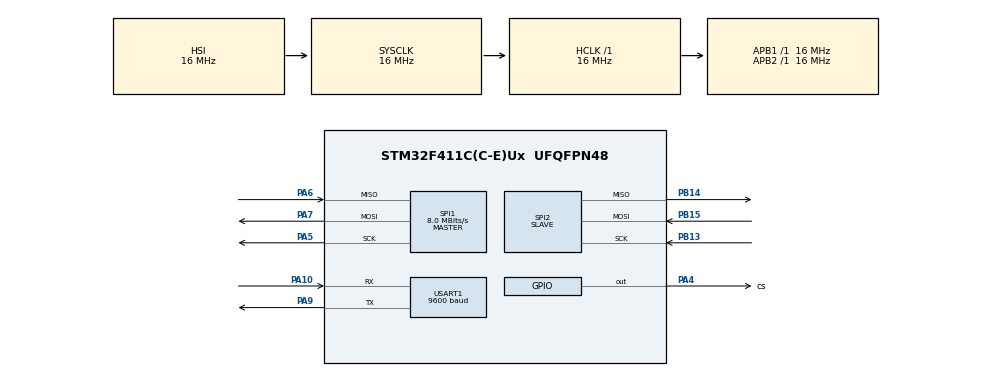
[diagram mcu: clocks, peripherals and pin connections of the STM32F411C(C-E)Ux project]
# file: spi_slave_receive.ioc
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Mcu.Family=STM32F4
Mcu.Name=STM32F411C(C-E)Ux
Mcu.Package=UFQFPN48
NVIC.PriorityGroup=NVIC_PRIORITYGROUP_4
NVIC.SPI2_IRQn=true\:0\:0\:false\:false\:true\:true\:true\:true
PA10.Mode=Asynchronous
PA10.Signal=USART1_RX
PA13.Mode=Serial_Wire
PA13.Signal=SYS_JTMS-SWDIO
PA14.Mode=Serial_Wire
PA14.Signal=SYS_JTCK-SWCLK
PA4.GPIO_Label=cs
PA4.Signal=GPIO_Output
PA5.Mode=Full_Duplex_Master
PA5.Signal=SPI1_SCK
PA6.Mode=Full_Duplex_Master
PA6.Signal=SPI1_MISO
PA7.Mode=Full_Duplex_Master
PA7.Signal=SPI1_MOSI
PA9.Mode=Asynchronous
PA9.Signal=USART1_TX
PB12.Signal=SPI2_NSS
PB13.Mode=Full_Duplex_Slave
PB13.Signal=SPI2_SCK
PB14.Mode=Full_Duplex_Slave
PB14.Signal=SPI2_MISO
PB15.Mode=Full_Duplex_Slave
PB15.Signal=SPI2_MOSI
PH0\ -\ OSC_IN.Mode=HSE-External-Oscillator
PH0\ -\ OSC_IN.Signal=RCC_OSC_IN
PH1\ -\ OSC_OUT.Mode=HSE-External-Oscillator
PH1\ -\ OSC_OUT.Signal=RCC_OSC_OUT
ProjectManager.HeapSize=0x200
ProjectManager.StackSize=0x400
ProjectManager.TargetToolchain=STM32CubeIDE
RCC.AHBFreq_Value=16000000
RCC.APB1Freq_Value=16000000
RCC.APB2Freq_Value=16000000
RCC.CortexFreq_Value=16000000
RCC.HSE_VALUE=25000000
RCC.HSI_VALUE=16000000
RCC.LSE_VALUE=32768
RCC.SYSCLKFreq_VALUE=16000000
RCC.VCOOutputFreq_Value=192000000
SPI1.CalculateBaudRate=8.0 MBits/s
SPI1.Direction=SPI_DIRECTION_2LINES
SPI1.Mode=SPI_MODE_MASTER
SPI1.VirtualType=VM_MASTER
SPI2.Direction=SPI_DIRECTION_2LINES
SPI2.Mode=SPI_MODE_SLAVE
SPI2.VirtualType=VM_SLAVE
USART1.BaudRate=9600
USART1.VirtualMode=VM_ASYNC
board=custom

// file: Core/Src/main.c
/* USER CODE BEGIN Header */
/* USER CODE END Header */
#include "main.h"

/* USER CODE BEGIN Includes */
#include "string.h"
/* USER CODE END Includes */

SPI_HandleTypeDef hspi1;
SPI_HandleTypeDef hspi2;

UART_HandleTypeDef huart1;

/* USER CODE BEGIN PV */
uint8_t tx_master[] = "len\r\n";
uint8_t rx_slave[1] = {0};
uint8_t rx_buffer[10];
uint8_t idx = 0;
/* USER CODE END PV */

void SystemClock_Config(void);
static void MX_GPIO_Init(void);
static void MX_SPI2_Init(void);
static void MX_USART1_UART_Init(void);
static void MX_SPI1_Init(void);

/* USER CODE BEGIN 0 */
void HAL_SPI_RxCpltCallback(SPI_HandleTypeDef *hspi)
{
	UNUSED(hspi);
	if(hspi->Instance == SPI2)
	{
		HAL_SPI_Receive_IT(&hspi2, rx_slave, 1);
		rx_buffer[idx++] = rx_slave[0];
		if(rx_slave[0] == '\n')
			idx = 0;

	}
}
/* USER CODE END 0 */

int main(void)
{

  /* MCU Configuration--------------------------------------------------------*/

  /* Reset of all peripherals, Initializes the Flash interface and the Systick. */
  HAL_Init();

  /* Configure the system clock */
  SystemClock_Config();

  /* Initialize all configured peripherals */
  MX_GPIO_Init();
  MX_SPI2_Init();
  MX_USART1_UART_Init();
  MX_SPI1_Init();
  /* USER CODE BEGIN 2 */
  HAL_SPI_Receive_IT(&hspi2, rx_slave, 1);
  HAL_SPI_Transmit(&hspi1, tx_master, 3, 1000);
  /* USER CODE END 2 */

  /* Infinite loop */

}

void SystemClock_Config(void)
{
  RCC_OscInitTypeDef RCC_OscInitStruct = {0};
  RCC_ClkInitTypeDef RCC_ClkInitStruct = {0};

  /** Configure the main internal regulator output voltage
  */
  __HAL_RCC_PWR_CLK_ENABLE();
  __HAL_PWR_VOLTAGESCALING_CONFIG(PWR_REGULATOR_VOLTAGE_SCALE1);

  /** Initializes the RCC Oscillators according to the specified parameters
  * in the RCC_OscInitTypeDef structure.
  */
  RCC_OscInitStruct.OscillatorType = RCC_OSCILLATORTYPE_HSI;
  RCC_OscInitStruct.HSIState = RCC_HSI_ON;
  RCC_OscInitStruct.HSICalibrationValue = RCC_HSICALIBRATION_DEFAULT;
  RCC_OscInitStruct.PLL.PLLState = RCC_PLL_NONE;
  if (HAL_RCC_OscConfig(&RCC_OscInitStruct) != HAL_OK)
  {
    Error_Handler();
  }

  /** Initializes the CPU, AHB and APB buses clocks
  */
  RCC_ClkInitStruct.ClockType = RCC_CLOCKTYPE_HCLK|RCC_CLOCKTYPE_SYSCLK
                              |RCC_CLOCKTYPE_PCLK1|RCC_CLOCKTYPE_PCLK2;
  RCC_ClkInitStruct.SYSCLKSource = RCC_SYSCLKSOURCE_HSI;
  RCC_ClkInitStruct.AHBCLKDivider = RCC_SYSCLK_DIV1;
  RCC_ClkInitStruct.APB1CLKDivider = RCC_HCLK_DIV1;
  RCC_ClkInitStruct.APB2CLKDivider = RCC_HCLK_DIV1;

  if (HAL_RCC_ClockConfig(&RCC_ClkInitStruct, FLASH_LATENCY_0) != HAL_OK)
  {
    Error_Handler();
  }
}

static void MX_SPI1_Init(void)
{

  /* SPI1 parameter configuration*/
  hspi1.Instance = SPI1;
  hspi1.Init.Mode = SPI_MODE_MASTER;
  hspi1.Init.Direction = SPI_DIRECTION_2LINES;
  hspi1.Init.DataSize = SPI_DATASIZE_8BIT;
  hspi1.Init.CLKPolarity = SPI_POLARITY_LOW;
  hspi1.Init.CLKPhase = SPI_PHASE_1EDGE;
  hspi1.Init.NSS = SPI_NSS_SOFT;
  hspi1.Init.BaudRatePrescaler = SPI_BAUDRATEPRESCALER_2;
  hspi1.Init.FirstBit = SPI_FIRSTBIT_MSB;
  hspi1.Init.TIMode = SPI_TIMODE_DISABLE;
  hspi1.Init.CRCCalculation = SPI_CRCCALCULATION_DISABLE;
  hspi1.Init.CRCPolynomial = 10;
  if (HAL_SPI_Init(&hspi1) != HAL_OK)
  {
    Error_Handler();
  }

}

static void MX_SPI2_Init(void)
{

  /* SPI2 parameter configuration*/
  hspi2.Instance = SPI2;
  hspi2.Init.Mode = SPI_MODE_SLAVE;
  hspi2.Init.Direction = SPI_DIRECTION_2LINES;
  hspi2.Init.DataSize = SPI_DATASIZE_8BIT;
  hspi2.Init.CLKPolarity = SPI_POLARITY_LOW;
  hspi2.Init.CLKPhase = SPI_PHASE_1EDGE;
  hspi2.Init.NSS = SPI_NSS_SOFT;
  hspi2.Init.FirstBit = SPI_FIRSTBIT_MSB;
  hspi2.Init.TIMode = SPI_TIMODE_DISABLE;
  hspi2.Init.CRCCalculation = SPI_CRCCALCULATION_DISABLE;
  hspi2.Init.CRCPolynomial = 10;
  if (HAL_SPI_Init(&hspi2) != HAL_OK)
  {
    Error_Handler();
  }

}

static void MX_USART1_UART_Init(void)
{

  huart1.Instance = USART1;
  huart1.Init.BaudRate = 9600;
  huart1.Init.WordLength = UART_WORDLENGTH_8B;
  huart1.Init.StopBits = UART_STOPBITS_1;
  huart1.Init.Parity = UART_PARITY_NONE;
  huart1.Init.Mode = UART_MODE_TX_RX;
  huart1.Init.HwFlowCtl = UART_HWCONTROL_NONE;
  huart1.Init.OverSampling = UART_OVERSAMPLING_16;
  if (HAL_UART_Init(&huart1) != HAL_OK)
  {
    Error_Handler();
  }

}

static void MX_GPIO_Init(void)
{
  GPIO_InitTypeDef GPIO_InitStruct = {0};

  /* GPIO Ports Clock Enable */
  __HAL_RCC_GPIOH_CLK_ENABLE();
  __HAL_RCC_GPIOA_CLK_ENABLE();
  __HAL_RCC_GPIOB_CLK_ENABLE();

  /*Configure GPIO pin Output Level */
  HAL_GPIO_WritePin(cs_GPIO_Port, cs_Pin, GPIO_PIN_RESET);

  /*Configure GPIO pin : cs_Pin */
  GPIO_InitStruct.Pin = cs_Pin;
  GPIO_InitStruct.Mode = GPIO_MODE_OUTPUT_PP;
  GPIO_InitStruct.Pull = GPIO_NOPULL;
  GPIO_InitStruct.Speed = GPIO_SPEED_FREQ_LOW;
  HAL_GPIO_Init(cs_GPIO_Port, &GPIO_InitStruct);

}

void Error_Handler(void)
{
}
